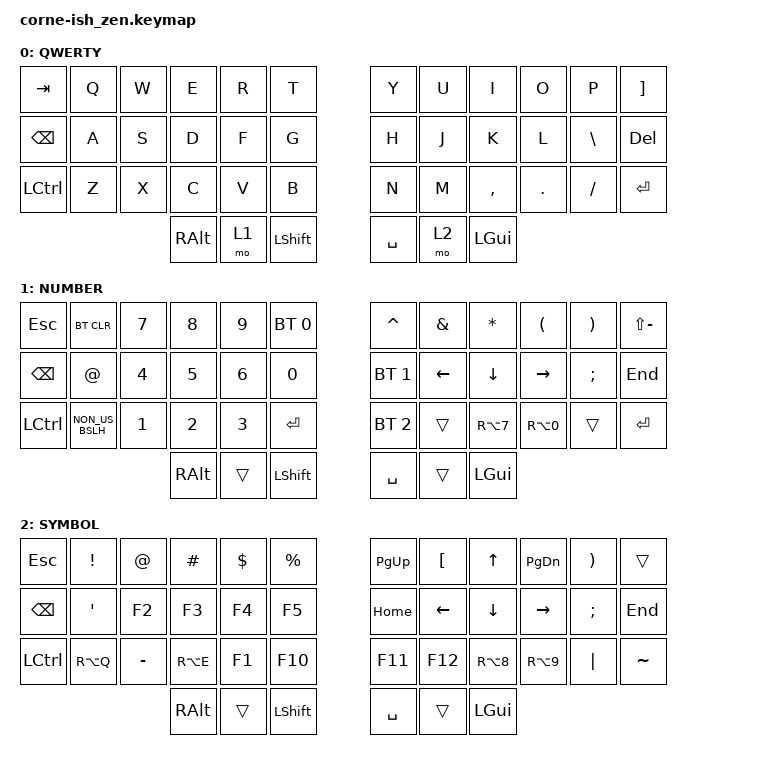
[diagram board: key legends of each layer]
/*
*
* Copyright (c) 2021 Darryl deHaan
* SPDX-License-Identifier: MIT
*
*/

#include <behaviors.dtsi>
#include <dt-bindings/zmk/keys.h>
#include <dt-bindings/zmk/bt.h>

/ {
        keymap {
                compatible = "zmk,keymap";

                default_layer {
                        label = "QWERTY";
// -----------------------------------------------------------------------------------------
// |  TAB |  Q  |  W  |  E  |  R  |  T  |   |  Y  |  U   |  I  |  O  |  P  | BKSP |
// | CTRL |  A  |  S  |  D  |  F  |  G  |   |  H  |  J   |  K  |  L  |  ;  |  '   |
// | SHFT |  Z  |  X  |  C  |  V  |  B  |   |  N  |  M   |  ,  |  .  |  /  | ESC  |
//                    | GUI | LWR | SPC |   | ENT | RSE  | ALT |
                        bindings = <
   &kp TAB   &kp Q &kp W &kp E &kp R &kp T   &kp Y &kp U  &kp I     &kp O   &kp P    &kp RBKT
   &kp BSPC  &kp A &kp S &kp D &kp F &kp G   &kp H &kp J  &kp K     &kp L   &kp BSLH &kp DEL
   &kp LCTRL &kp Z &kp X &kp C &kp V &kp B   &kp N &kp M  &kp COMMA &kp DOT &kp FSLH &kp ENTER
                  &kp RALT &mo 1 &kp LSHFT   &kp SPACE &mo 2 &kp LGUI
                        >;
                };
                lower_layer {
                        label = "NUMBER";
// -----------------------------------------------------------------------------------------
// |  ESC |  1  |  2  |  3  |  4  |  5  |   |  6  |  7  |  8  |  9  |  0  | BKSP |
// | BTCLR| BT1 | BT2 | BT3 | BT4 | BT5 |   | LFT | DWN |  UP | RGT |     |      |
// | SHFT |     |     |     |     |     |   |     |     |     |     |     |      |
//                    | GUI |     | SPC |   | ENT |     | ALT |
                        bindings = <
   &kp ESC    &bt BT_CLR     &kp N7       &kp N8       &kp N9       &bt BT_SEL 0        &kp CARET     &kp AMPS   &kp STAR   &kp LPAR    &kp RPAR   &kp LS(MINUS)
   &kp BSPC   &kp AT         &kp N4       &kp N5       &kp N6       &kp N0              &bt BT_SEL 1  &kp LEFT   &kp DOWN   &kp RIGHT   &kp SEMI   &kp END
   &kp LCTRL  &kp NON_US_BSLH&kp N1       &kp N2       &kp N3       &kp ENTER           &bt BT_SEL 2  &trans     &kp RA(N7) &kp RA(N0)  &trans     &kp ENTER
                          	              &kp RALT     &trans       &kp LSHFT           &kp SPACE     &trans     &kp LGUI
                        >;
                };

                raise_layer {
                        label = "SYMBOL";
// -----------------------------------------------------------------------------------------
// |  ESC |  !  |  @  |  #  |  $  |  %  |   |  ^  |  &  |  *  |  (  |  )  | BKSP |
// | CTRL |INT1 |INT2 |INT3 |INT4 |INT5 |   |  -  |  =  |  [  |  ]  |  \  |  `   |
// | SHFT |INT6 |INT7 |INT8 |INT9 |     |   |  _  |  +  |  {  |  }  | "|" |  ~   |
//                    | GUI |     | SPC |   | ENT |     | ALT |
                        bindings = <
   &kp  ESC    &kp EXCL   &kp AT     &kp HASH   &kp DLLR   &kp PRCNT     &kp PG_UP &kp LBKT  &kp UP     &kp PG_DN  &kp RPAR &trans
   &kp BSPC    &kp SQT    &kp F2     &kp F3     &kp F4     &kp F5        &kp HOME  &kp LEFT  &kp DOWN   &kp RIGHT  &kp SEMI &kp END
   &kp LCTRL   &kp RA(Q)  &kp MINUS  &kp RA(E)  &kp F1     &kp F10       &kp F11   &kp F12   &kp RA(N8) &kp RA(N9) &kp PIPE &kp TILDE
                    	                  &kp RALT &trans   &kp LSHFT    &kp SPACE   &trans    &kp LGUI
                        >;
                };
        };
};
